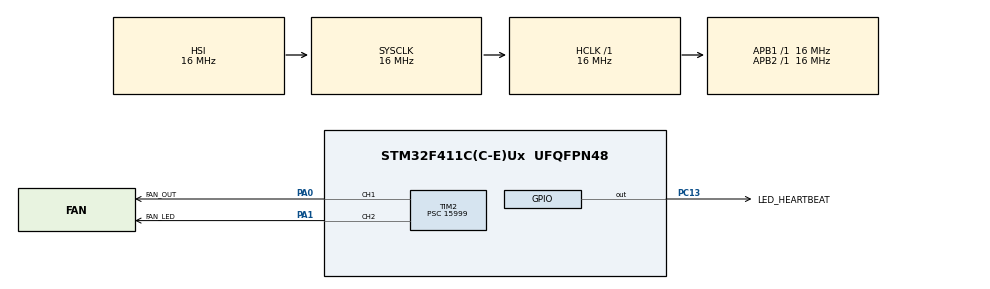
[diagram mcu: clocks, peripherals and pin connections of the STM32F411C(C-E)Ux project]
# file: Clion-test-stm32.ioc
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IWDG.Prescaler=IWDG_PRESCALER_32
IWDG.Reload=2000
Mcu.Family=STM32F4
Mcu.Name=STM32F411C(C-E)Ux
Mcu.Package=UFQFPN48
NVIC.PriorityGroup=NVIC_PRIORITYGROUP_4
NVIC.TIM2_IRQn=true\:1\:0\:true\:false\:true\:true\:true\:true
NVIC.TIM3_IRQn=true\:2\:0\:true\:false\:true\:true\:true\:true
PA0-WKUP.GPIO_Label=FAN_OUT
PA0-WKUP.GPIO_PuPd=GPIO_PULLDOWN
PA0-WKUP.Signal=S_TIM2_CH1_ETR
PA1.GPIO_Label=FAN_LED
PA1.GPIO_PuPd=GPIO_PULLDOWN
PA1.Signal=S_TIM2_CH2
PA13.Mode=Serial_Wire
PA13.Signal=SYS_JTMS-SWDIO
PA14.Mode=Serial_Wire
PA14.Signal=SYS_JTCK-SWCLK
PC13-ANTI_TAMP.GPIO_Label=LED_HEARTBEAT
PC13-ANTI_TAMP.GPIO_PuPd=GPIO_NOPULL
PC13-ANTI_TAMP.Signal=GPIO_Output
ProjectManager.HeapSize=0x200
ProjectManager.StackSize=0x400
ProjectManager.TargetToolchain=CMake
RCC.AHBFreq_Value=16000000
RCC.APB1Freq_Value=16000000
RCC.APB2Freq_Value=16000000
RCC.CortexFreq_Value=16000000
RCC.HSE_VALUE=25000000
RCC.HSI_VALUE=16000000
RCC.LSE_VALUE=32768
RCC.SYSCLKFreq_VALUE=16000000
RCC.VCOOutputFreq_Value=192000000
SH.S_TIM2_CH1_ETR.0=TIM2_CH1,PWM Generation1 CH1
SH.S_TIM2_CH2.0=TIM2_CH2,PWM Generation2 CH2
TIM2.AutoReloadPreload=TIM_AUTORELOAD_PRELOAD_ENABLE
TIM2.Channel-PWM\ Generation1\ CH1=TIM_CHANNEL_1
TIM2.Channel-PWM\ Generation2\ CH2=TIM_CHANNEL_2
TIM2.Period=59999
TIM2.Prescaler=15999
TIM2.Pulse-PWM\ Generation1\ CH1=15000
TIM2.Pulse-PWM\ Generation2\ CH2=15000
TIM3.AutoReloadPreload=TIM_AUTORELOAD_PRELOAD_ENABLE
TIM3.Period=499
TIM3.Prescaler=15999
VP_IWDG_VS_IWDG.Mode=IWDG_Activate
VP_TIM2_VS_ClockSourceINT.Mode=Internal
VP_TIM3_VS_ClockSourceINT.Mode=Internal
board=custom

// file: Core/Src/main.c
/* USER CODE BEGIN Header */
/**
  ******************************************************************************
  * @file           : main.c
  * @brief          : Main program body
  ******************************************************************************
  * @attention
  *
  * Copyright (c) 2026 STMicroelectronics.
  * All rights reserved.
  *
  * This software is licensed under terms that can be found in the LICENSE file
  * in the root directory of this software component.
  * If no LICENSE file comes with this software, it is provided AS-IS.
  *
  ******************************************************************************
  */
/* USER CODE END Header */
#include "main.h"

/* USER CODE BEGIN Includes */
#include "app.h"

/* USER CODE END Includes */

IWDG_HandleTypeDef hiwdg;

TIM_HandleTypeDef htim2;
TIM_HandleTypeDef htim3;

void SystemClock_Config(void);
static void MX_GPIO_Init(void);
static void MX_IWDG_Init(void);
static void MX_TIM2_Init(void);
static void MX_TIM3_Init(void);

int main(void)
{

  /* MCU Configuration--------------------------------------------------------*/

  /* Reset of all peripherals, Initializes the Flash interface and the Systick. */
  HAL_Init();

  /* Configure the system clock */
  SystemClock_Config();

  /* Initialize all configured peripherals */
  MX_GPIO_Init();
  MX_IWDG_Init();
  MX_TIM2_Init();
  MX_TIM3_Init();
  /* USER CODE BEGIN 2 */

  AppParams appParams = {
    .Watch_Dog_Counter = &hiwdg
  };

  App_Main(appParams);

  /* USER CODE END 2 */

  /* Infinite loop */
  while (1)
  {

  }
}

void SystemClock_Config(void)
{
  RCC_OscInitTypeDef RCC_OscInitStruct = {0};
  RCC_ClkInitTypeDef RCC_ClkInitStruct = {0};

  /** Configure the main internal regulator output voltage
  */
  __HAL_RCC_PWR_CLK_ENABLE();
  __HAL_PWR_VOLTAGESCALING_CONFIG(PWR_REGULATOR_VOLTAGE_SCALE1);

  /** Initializes the RCC Oscillators according to the specified parameters
  * in the RCC_OscInitTypeDef structure.
  */
  RCC_OscInitStruct.OscillatorType = RCC_OSCILLATORTYPE_HSI|RCC_OSCILLATORTYPE_LSI;
  RCC_OscInitStruct.HSIState = RCC_HSI_ON;
  RCC_OscInitStruct.HSICalibrationValue = RCC_HSICALIBRATION_DEFAULT;
  RCC_OscInitStruct.LSIState = RCC_LSI_ON;
  RCC_OscInitStruct.PLL.PLLState = RCC_PLL_NONE;
  if (HAL_RCC_OscConfig(&RCC_OscInitStruct) != HAL_OK)
  {
    Error_Handler();
  }

  /** Initializes the CPU, AHB and APB buses clocks
  */
  RCC_ClkInitStruct.ClockType = RCC_CLOCKTYPE_HCLK|RCC_CLOCKTYPE_SYSCLK
                              |RCC_CLOCKTYPE_PCLK1|RCC_CLOCKTYPE_PCLK2;
  RCC_ClkInitStruct.SYSCLKSource = RCC_SYSCLKSOURCE_HSI;
  RCC_ClkInitStruct.AHBCLKDivider = RCC_SYSCLK_DIV1;
  RCC_ClkInitStruct.APB1CLKDivider = RCC_HCLK_DIV1;
  RCC_ClkInitStruct.APB2CLKDivider = RCC_HCLK_DIV1;

  if (HAL_RCC_ClockConfig(&RCC_ClkInitStruct, FLASH_LATENCY_0) != HAL_OK)
  {
    Error_Handler();
  }
}

static void MX_IWDG_Init(void)
{

  hiwdg.Instance = IWDG;
  hiwdg.Init.Prescaler = IWDG_PRESCALER_32;
  hiwdg.Init.Reload = 2000;
  if (HAL_IWDG_Init(&hiwdg) != HAL_OK)
  {
    Error_Handler();
  }

}

static void MX_TIM2_Init(void)
{

  TIM_ClockConfigTypeDef sClockSourceConfig = {0};
  TIM_MasterConfigTypeDef sMasterConfig = {0};
  TIM_OC_InitTypeDef sConfigOC = {0};

  htim2.Instance = TIM2;
  htim2.Init.Prescaler = 15999;
  htim2.Init.CounterMode = TIM_COUNTERMODE_UP;
  htim2.Init.Period = 59999;
  htim2.Init.ClockDivision = TIM_CLOCKDIVISION_DIV1;
  htim2.Init.AutoReloadPreload = TIM_AUTORELOAD_PRELOAD_ENABLE;
  if (HAL_TIM_Base_Init(&htim2) != HAL_OK)
  {
    Error_Handler();
  }
  sClockSourceConfig.ClockSource = TIM_CLOCKSOURCE_INTERNAL;
  if (HAL_TIM_ConfigClockSource(&htim2, &sClockSourceConfig) != HAL_OK)
  {
    Error_Handler();
  }
  if (HAL_TIM_PWM_Init(&htim2) != HAL_OK)
  {
    Error_Handler();
  }
  sMasterConfig.MasterOutputTrigger = TIM_TRGO_RESET;
  sMasterConfig.MasterSlaveMode = TIM_MASTERSLAVEMODE_DISABLE;
  if (HAL_TIMEx_MasterConfigSynchronization(&htim2, &sMasterConfig) != HAL_OK)
  {
    Error_Handler();
  }
  sConfigOC.OCMode = TIM_OCMODE_PWM1;
  sConfigOC.Pulse = 15000;
  sConfigOC.OCPolarity = TIM_OCPOLARITY_HIGH;
  sConfigOC.OCFastMode = TIM_OCFAST_DISABLE;
  if (HAL_TIM_PWM_ConfigChannel(&htim2, &sConfigOC, TIM_CHANNEL_1) != HAL_OK)
  {
    Error_Handler();
  }
  if (HAL_TIM_PWM_ConfigChannel(&htim2, &sConfigOC, TIM_CHANNEL_2) != HAL_OK)
  {
    Error_Handler();
  }
  HAL_TIM_MspPostInit(&htim2);

}

static void MX_TIM3_Init(void)
{

  TIM_ClockConfigTypeDef sClockSourceConfig = {0};
  TIM_MasterConfigTypeDef sMasterConfig = {0};

  htim3.Instance = TIM3;
  htim3.Init.Prescaler = 15999;
  htim3.Init.CounterMode = TIM_COUNTERMODE_UP;
  htim3.Init.Period = 499;
  htim3.Init.ClockDivision = TIM_CLOCKDIVISION_DIV1;
  htim3.Init.AutoReloadPreload = TIM_AUTORELOAD_PRELOAD_ENABLE;
  if (HAL_TIM_Base_Init(&htim3) != HAL_OK)
  {
    Error_Handler();
  }
  sClockSourceConfig.ClockSource = TIM_CLOCKSOURCE_INTERNAL;
  if (HAL_TIM_ConfigClockSource(&htim3, &sClockSourceConfig) != HAL_OK)
  {
    Error_Handler();
  }
  sMasterConfig.MasterOutputTrigger = TIM_TRGO_RESET;
  sMasterConfig.MasterSlaveMode = TIM_MASTERSLAVEMODE_DISABLE;
  if (HAL_TIMEx_MasterConfigSynchronization(&htim3, &sMasterConfig) != HAL_OK)
  {
    Error_Handler();
  }

}

static void MX_GPIO_Init(void)
{
  GPIO_InitTypeDef GPIO_InitStruct = {0};

  /* GPIO Ports Clock Enable */
  __HAL_RCC_GPIOC_CLK_ENABLE();
  __HAL_RCC_GPIOA_CLK_ENABLE();

  /*Configure GPIO pin Output Level */
  HAL_GPIO_WritePin(LED_HEARTBEAT_GPIO_Port, LED_HEARTBEAT_Pin, GPIO_PIN_RESET);

  /*Configure GPIO pin : LED_HEARTBEAT_Pin */
  GPIO_InitStruct.Pin = LED_HEARTBEAT_Pin;
  GPIO_InitStruct.Mode = GPIO_MODE_OUTPUT_PP;
  GPIO_InitStruct.Pull = GPIO_NOPULL;
  GPIO_InitStruct.Speed = GPIO_SPEED_FREQ_LOW;
  HAL_GPIO_Init(LED_HEARTBEAT_GPIO_Port, &GPIO_InitStruct);

}

void Error_Handler(void)
{
  __disable_irq();
  while (1)
  {
  }
}
